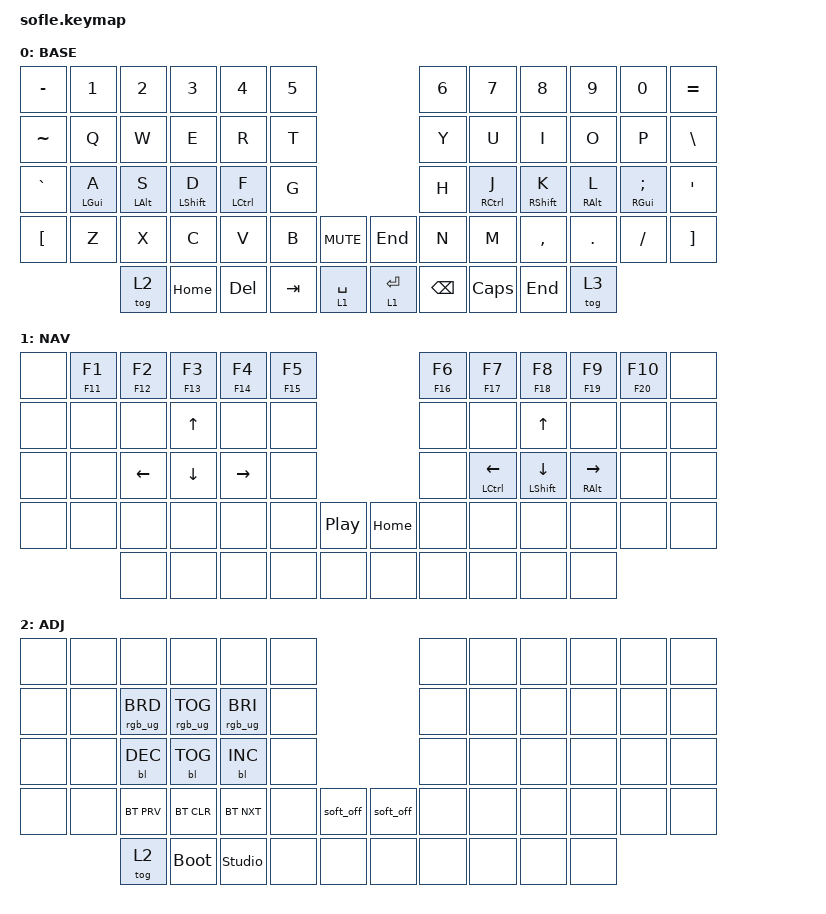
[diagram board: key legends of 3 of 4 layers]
/*
 * Copyright (c) 2020 The ZMK Contributors
 *
 * SPDX-License-Identifier: MIT
 */

#include <behaviors.dtsi>
#include <dt-bindings/zmk/backlight.h>
#include <dt-bindings/zmk/bt.h>
#include <dt-bindings/zmk/keys.h>
#include <dt-bindings/zmk/rgb.h>

//Encoder Support
//Alps Alpine EC11N1524402: 30 Detent, 15PPR, 2 Channel, Quadrature, 15000 Cycle

&lt {
    tapping-term-ms = <280>;
    quick-tap-ms = <175>;
    require-prior-idle-ms = <150>;
    flavor = "balanced";
};

&mt {
    tapping-term-ms = <280>;
    quick-tap-ms = <175>;
    require-prior-idle-ms = <150>;
    flavor = "balanced";
};

/ {
    left_encoder: encoder_left {
        compatible = "alps,ec11";
        label = "LEFT_ENCODER";
        a-gpios = <&pro_micro 21 (GPIO_ACTIVE_HIGH | GPIO_PULL_UP)>;
        b-gpios = <&pro_micro 20 (GPIO_ACTIVE_HIGH | GPIO_PULL_UP)>;
        steps = <60>;
    };

    right_encoder: encoder_right {
        compatible = "alps,ec11";
        label = "RIGHT_ENCODER";
        a-gpios = <&pro_micro 21 (GPIO_ACTIVE_HIGH | GPIO_PULL_UP)>;
        b-gpios = <&pro_micro 20 (GPIO_ACTIVE_HIGH | GPIO_PULL_UP)>;
        steps = <60>;
    };

    sensors {
        compatible = "zmk,keymap-sensors";
        sensors = <&left_encoder &right_encoder>;
        triggers-per-rotation = <30>;
    };
};

/ {
    combos {
        compatible = "zmk,combos";

        move_window {
            bindings = <&kp LS(LG(LEFT_ARROW))>;
            key-positions = <15 20>;
        };

        l_esc {
            bindings = <&kp ESCAPE>;
            key-positions = <26 27 28>;
        };

        r_esc {
            bindings = <&kp ESCAPE>;
            key-positions = <31 32 33>;
        };

        next_input {
            bindings = <&kp LS(LALT)>;
            key-positions = <54 55>;
        };
    };

    keymap {
        compatible = "zmk,keymap";

        BASE {
            bindings = <
&kp MINUS  &kp N1      &kp N2          &kp N3       &kp N4       &kp N5                               &kp N6    &kp N7       &kp N8       &kp N9      &kp N0         &kp EQUAL
&kp TILDE  &kp Q       &kp W           &kp E        &kp R        &kp T                                &kp Y     &kp U        &kp I        &kp O       &kp P          &kp BSLH
&kp GRAVE  &mt LGUI A  &mt LEFT_ALT S  &mt LSHFT D  &mt LCTRL F  &kp G                                &kp H     &mt RCTRL J  &mt RSHFT K  &mt RALT L  &mt RGUI SEMI  &kp SQT
&kp LBKT   &kp Z       &kp X           &kp C        &kp V        &kp B    &kp C_MUTE     &kp END      &kp N     &kp M        &kp COMMA    &kp DOT     &kp FSLH       &kp RBKT
                       &tog 2          &kp HOME     &kp DEL      &kp TAB  &lt 1 SPACE    &lt 1 ENTER  &kp BSPC  &kp CAPS     &kp END      &tog 3
            >;

            sensor-bindings =
                <&inc_dec_kp C_VOL_DN C_VOL_UP>,
                <&inc_dec_kp LC(RIGHT_ARROW) LC(LEFT_ARROW)>;
        };

        NAV {
            bindings = <
&none  &mt F11 F1  &mt F12 F2  &mt F13 F3  &mt F14 F4  &mt F15 F5                        &mt F16 F6  &mt F17 F7      &mt F18 F8            &mt F19 F9      &mt F20 F10  &none
&none  &none       &none       &kp UP      &none       &none                             &none       &none           &kp UP                &none           &none        &none
&none  &none       &kp LEFT    &kp DOWN    &kp RIGHT   &none                             &none       &mt LCTRL LEFT  &mt LSHFT DOWN_ARROW  &mt RALT RIGHT  &none        &none
&none  &none       &none       &none       &none       &none       &kp C_PP    &kp HOME  &none       &none           &none                 &none           &none        &none
                   &none       &none       &none       &none       &none       &none     &none       &none           &none                 &none
            >;

            sensor-bindings =
                <&inc_dec_kp C_NEXT C_PREV>,
                <&inc_dec_kp PG_UP PG_DN>;
        };

        ADJ {
            bindings = <
&none  &none  &none            &none            &none            &none                          &none  &none  &none  &none  &none  &none
&none  &none  &rgb_ug RGB_BRD  &rgb_ug RGB_TOG  &rgb_ug RGB_BRI  &none                          &none  &none  &none  &none  &none  &none
&none  &none  &bl BL_DEC       &bl BL_TOG       &bl BL_INC       &none                          &none  &none  &none  &none  &none  &none
&none  &none  &bt BT_PRV       &bt BT_CLR       &bt BT_NXT       &none  &soft_off    &soft_off  &none  &none  &none  &none  &none  &none
              &tog 2           &bootloader      &studio_unlock   &none  &none        &none      &none  &none  &none  &none
            >;
        };

        GAME {
            bindings = <
&none  &kp N1     &kp N2  &kp N3  &kp N4  &kp N5                                   &kp N6        &kp N7    &kp N8    &kp N9     &kp N0   &none
&none  &kp TAB    &kp Q   &kp W   &kp E   &kp R                                    &kp C_VOL_UP  &kp Q     &kp UP    &kp E      &kp ESC  &none
&kp M  &kp LSHFT  &kp A   &kp S   &kp D   &kp F                                    &kp C_VOL_DN  &kp LEFT  &kp DOWN  &kp RIGHT  &none    &none
&kp G  &kp LCTRL  &kp Z   &kp X   &kp C   &kp V     &kp C_MUTE    &rgb_ug RGB_TOG  &kp F1        &kp F2    &kp F3    &kp F4     &kp F5   &kp F6
                  &trans  &none   &none   &kp LALT  &kp SPACE     &kp ENTER        &tog 3        &none
            >;

            sensor-bindings = <&inc_dec_kp C_VOL_DN C_VOL_UP>;
        };
    };
};
